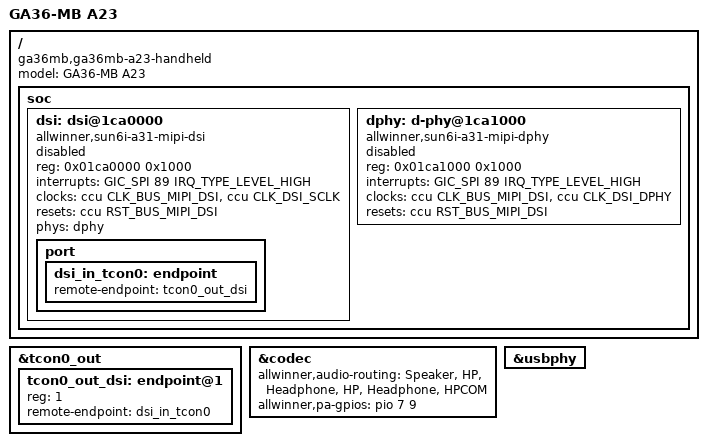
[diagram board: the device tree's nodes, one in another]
#include "sun8i-a23.dtsi"

/ {
    model = "GA36-MB A23";
    compatible = "ga36mb,ga36mb-a23-handheld",
    "allwinner,sun8i-a23";

    soc {
		dsi: dsi@1ca0000 {
			compatible = "allwinner,sun6i-a31-mipi-dsi";
			reg = <0x01ca0000 0x1000>;
			interrupts = <GIC_SPI 89 IRQ_TYPE_LEVEL_HIGH>;
			clocks = <&ccu CLK_BUS_MIPI_DSI>, <&ccu CLK_DSI_SCLK>;
			clock-names = "bus", "mod";
			resets = <&ccu RST_BUS_MIPI_DSI>;
			phys = <&dphy>;
			phy-names = "dphy";
			status = "disabled";
			#address-cells = <1>;
			#size-cells = <0>;

			port {
				dsi_in_tcon0: endpoint {
					remote-endpoint = <&tcon0_out_dsi>;
				};
			};
		};
		dphy: d-phy@1ca1000 {
			compatible = "allwinner,sun6i-a31-mipi-dphy";
			reg = <0x01ca1000 0x1000>;
			interrupts = <GIC_SPI 89 IRQ_TYPE_LEVEL_HIGH>;
			clocks = <&ccu CLK_BUS_MIPI_DSI>, <&ccu CLK_DSI_DPHY>;
			clock-names = "bus", "mod";
			resets = <&ccu RST_BUS_MIPI_DSI>;
			status = "disabled";
			#phy-cells = <0>;
		};
    };
};

#include "ga36mb.dtsi"

&tcon0_out {
	#address-cells = <1>;
	#size-cells = <0>;

	tcon0_out_dsi: endpoint@1 {
		reg = <1>;
		remote-endpoint = <&dsi_in_tcon0>;
	};
};

&codec {
    allwinner,audio-routing = "Speaker", "HP",
        "Headphone", "HP",
        "Headphone", "HPCOM";	/* direct drive: the jack's return is HPCOM */
    allwinner,pa-gpios = <&pio 7 9 GPIO_ACTIVE_HIGH>; /* PH09 */
};

/* The OTG port is a USB device port here: MTP and the serial console on a PC.
 *
 * No usb0_vbus-supply: the GA36-MB has nothing to put 5 V on the port (issue #29), and the AXP
 * only registers drivevbus with x-powers,drive-vbus-en, which this PMIC node hasn't, so usbphy
 * waited for it forever ("Couldn't get regulator usb0_vbus... Deferring probe") and took musb,
 * EHCI and OHCI with it: nothing on the PC, not even the serial console.
 *
 * No ID pin: before it had a pull-up, PH8 put the port in host mode at every boot (musb:
 * "VBUS_ERROR in a_wait_vrise", issue #42), and host mode can't work with no 5 V to give. In OTG
 * mode with no ID GPIO the PHY makes the port a device, whatever this board does with PH8.
 * Host mode, for a powered hub, is a write away:
 *   echo host > /sys/bus/platform/devices/musb-hdrc.*.auto/mode   (peripheral to go back) */
&usbphy {
    /delete-property/ usb0_id_det-gpios;
};
